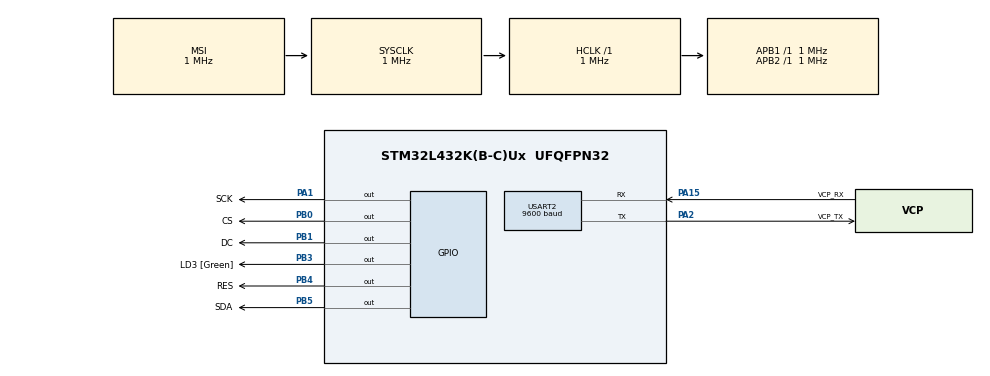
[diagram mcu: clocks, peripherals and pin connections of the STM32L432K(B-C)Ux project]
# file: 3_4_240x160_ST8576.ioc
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Mcu.Family=STM32L4
Mcu.Name=STM32L432K(B-C)Ux
Mcu.Package=UFQFPN32
NVIC.PriorityGroup=NVIC_PRIORITYGROUP_4
PA0.GPIO_Label=MCO [High speed clock in]
PA0.Mode=HSE-External-Clock-Source-for-LittleOrca
PA0.Signal=RCC_CK_IN
PA1.GPIO_Label=SCK
PA1.GPIO_Speed=GPIO_SPEED_FREQ_VERY_HIGH
PA1.PinState=GPIO_PIN_SET
PA1.Signal=GPIO_Output
PA13\ (JTMS-SWDIO).GPIO_Label=SWDIO
PA13\ (JTMS-SWDIO).Mode=Serial_Wire
PA13\ (JTMS-SWDIO).Signal=SYS_JTMS-SWDIO
PA14\ (JTCK-SWCLK).GPIO_Label=SWCLK
PA14\ (JTCK-SWCLK).Mode=Serial_Wire
PA14\ (JTCK-SWCLK).Signal=SYS_JTCK-SWCLK
PA15\ (JTDI).GPIO_Label=VCP_RX
PA15\ (JTDI).Mode=Asynchronous
PA15\ (JTDI).Signal=USART2_RX
PA2.GPIO_Label=VCP_TX
PA2.Mode=Asynchronous
PA2.Signal=USART2_TX
PB0.GPIO_Label=CS
PB0.GPIO_ModeDefaultOutputPP=GPIO_MODE_OUTPUT_PP
PB0.GPIO_PuPd=GPIO_NOPULL
PB0.GPIO_Speed=GPIO_SPEED_FREQ_VERY_HIGH
PB0.PinState=GPIO_PIN_SET
PB0.Signal=GPIO_Output
PB1.GPIO_Label=DC
PB1.GPIO_ModeDefaultOutputPP=GPIO_MODE_OUTPUT_PP
PB1.GPIO_PuPd=GPIO_NOPULL
PB1.GPIO_Speed=GPIO_SPEED_FREQ_VERY_HIGH
PB1.PinState=GPIO_PIN_SET
PB1.Signal=GPIO_Output
PB3\ (JTDO-TRACESWO).GPIO_Label=LD3 [Green]
PB3\ (JTDO-TRACESWO).Signal=GPIO_Output
PB4\ (NJTRST).GPIO_Label=RES
PB4\ (NJTRST).GPIO_Speed=GPIO_SPEED_FREQ_VERY_HIGH
PB4\ (NJTRST).PinState=GPIO_PIN_SET
PB4\ (NJTRST).Signal=GPIO_Output
PB5.GPIO_Label=SDA
PB5.GPIO_Speed=GPIO_SPEED_FREQ_VERY_HIGH
PB5.PinState=GPIO_PIN_SET
PB5.Signal=GPIO_Output
PC14-OSC32_IN\ (PC14).Mode=LSE-External-Oscillator
PC14-OSC32_IN\ (PC14).Signal=RCC_OSC32_IN
PC15-OSC32_OUT\ (PC15).Mode=LSE-External-Oscillator
PC15-OSC32_OUT\ (PC15).Signal=RCC_OSC32_OUT
ProjectManager.HeapSize=0x200
ProjectManager.StackSize=0x400
ProjectManager.TargetToolchain=STM32CubeIDE
RCC.ADCFreq_Value=4000000
RCC.AHBFreq_Value=1000000
RCC.APB1Freq_Value=1000000
RCC.APB1TimFreq_Value=1000000
RCC.APB2Freq_Value=1000000
RCC.APB2TimFreq_Value=1000000
RCC.CortexFreq_Value=1000000
RCC.HCLKFreq_Value=1000000
RCC.HSE_VALUE=8000000
RCC.HSI16_VALUE=16000000
RCC.HSI48_VALUE=48000000
RCC.HSI_VALUE=16000000
RCC.MSIClockRange=RCC_MSIRANGE_4
RCC.MSI_VALUE=1000000
RCC.PLLMUL=RCC_PLLMUL_4
RCC.PLLN=16
RCC.SYSCLKFreq_VALUE=1000000
RCC.USBFreq_Value=4000000
RCC.VCOOutputFreq_Value=16000000
USART2.BaudRate=9600
USART2.VirtualMode-Asynchronous=VM_ASYNC
board=NUCLEO-L432KC

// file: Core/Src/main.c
/* USER CODE BEGIN Header */
/**
  ******************************************************************************
  * @file           : main.c
  * @brief          : Main program body
  ******************************************************************************
  * @attention
  *
  * <h2><center>&copy; Copyright (c) 2021 STMicroelectronics.
  * All rights reserved.</center></h2>
  *
  * This software component is licensed by ST under BSD 3-Clause license,
  * the "License"; You may not use this file except in compliance with the
  * License. You may obtain a copy of the License at:
  *                        opensource.org/licenses/BSD-3-Clause
  *
  ******************************************************************************
  */
/* USER CODE END Header */
#include "main.h"
#include "usart.h"
#include "gpio.h"

void SystemClock_Config(void);
/* USER CODE BEGIN PFP */
void screenMain(void);

/* USER CODE END PFP */

int main(void)
{

  /* MCU Configuration--------------------------------------------------------*/

  /* Reset of all peripherals, Initializes the Flash interface and the Systick. */
  HAL_Init();

  /* Configure the system clock */
  SystemClock_Config();

  /* Initialize all configured peripherals */
  MX_GPIO_Init();
  MX_USART2_UART_Init();
  /* USER CODE BEGIN 2 */
    screenMain();

  /* USER CODE END 2 */

  /* Infinite loop */
  while (1)
  {

  }
}

void SystemClock_Config(void)
{
  RCC_OscInitTypeDef RCC_OscInitStruct = {0};
  RCC_ClkInitTypeDef RCC_ClkInitStruct = {0};
  RCC_PeriphCLKInitTypeDef PeriphClkInit = {0};

  /** Configure LSE Drive Capability
  */
  HAL_PWR_EnableBkUpAccess();
  __HAL_RCC_LSEDRIVE_CONFIG(RCC_LSEDRIVE_LOW);
  /** Initializes the RCC Oscillators according to the specified parameters
  * in the RCC_OscInitTypeDef structure.
  */
  RCC_OscInitStruct.OscillatorType = RCC_OSCILLATORTYPE_LSE|RCC_OSCILLATORTYPE_MSI;
  RCC_OscInitStruct.LSEState = RCC_LSE_ON;
  RCC_OscInitStruct.MSIState = RCC_MSI_ON;
  RCC_OscInitStruct.MSICalibrationValue = 0;
  RCC_OscInitStruct.MSIClockRange = RCC_MSIRANGE_4;
  RCC_OscInitStruct.PLL.PLLState = RCC_PLL_NONE;
  if (HAL_RCC_OscConfig(&RCC_OscInitStruct) != HAL_OK)
  {
    Error_Handler();
  }
  /** Initializes the CPU, AHB and APB buses clocks
  */
  RCC_ClkInitStruct.ClockType = RCC_CLOCKTYPE_HCLK|RCC_CLOCKTYPE_SYSCLK
                              |RCC_CLOCKTYPE_PCLK1|RCC_CLOCKTYPE_PCLK2;
  RCC_ClkInitStruct.SYSCLKSource = RCC_SYSCLKSOURCE_MSI;
  RCC_ClkInitStruct.AHBCLKDivider = RCC_SYSCLK_DIV1;
  RCC_ClkInitStruct.APB1CLKDivider = RCC_HCLK_DIV1;
  RCC_ClkInitStruct.APB2CLKDivider = RCC_HCLK_DIV1;

  if (HAL_RCC_ClockConfig(&RCC_ClkInitStruct, FLASH_LATENCY_0) != HAL_OK)
  {
    Error_Handler();
  }
  PeriphClkInit.PeriphClockSelection = RCC_PERIPHCLK_USART2;
  PeriphClkInit.Usart2ClockSelection = RCC_USART2CLKSOURCE_PCLK1;
  if (HAL_RCCEx_PeriphCLKConfig(&PeriphClkInit) != HAL_OK)
  {
    Error_Handler();
  }
  /** Configure the main internal regulator output voltage
  */
  if (HAL_PWREx_ControlVoltageScaling(PWR_REGULATOR_VOLTAGE_SCALE1) != HAL_OK)
  {
    Error_Handler();
  }
  /** Enable MSI Auto calibration
  */
  HAL_RCCEx_EnableMSIPLLMode();
}

void Error_Handler(void)
{
  __disable_irq();
  while (1)
  {
  }
}

/************************ (C) COPYRIGHT STMicroelectronics *****END OF FILE****/
